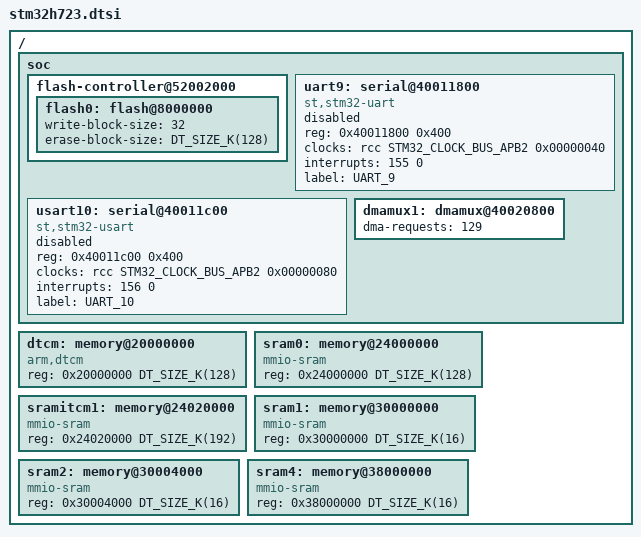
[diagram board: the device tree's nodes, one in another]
/*
 * Copyright (c) 2020 Alexander Kozhinov <AlexanderKozhinov@yandex.com>
 * SPDX-License-Identifier: Apache-2.0
 */

#include <st/h7/stm32h7.dtsi>

/ {
	soc {
		flash-controller@52002000 {
			flash0: flash@8000000 {
				write-block-size = <32>;
				erase-block-size = <DT_SIZE_K(128)>;
			};
		};

		uart9: serial@40011800 {
			compatible = "st,stm32-uart";
			reg = <0x40011800 0x400>;
			clocks = <&rcc STM32_CLOCK_BUS_APB2 0x00000040>;
			interrupts = <155 0>;
			status = "disabled";
			label = "UART_9";
		};

		usart10: serial@40011c00 {
			compatible = "st,stm32-usart", "st,stm32-uart";
			reg = <0x40011c00 0x400>;
			clocks = <&rcc STM32_CLOCK_BUS_APB2 0x00000080>;
			interrupts = <156 0>;
			status = "disabled";
			label = "UART_10";
		};

		dmamux1: dmamux@40020800 {
			dma-requests= <129>;
		};
	};

	/* DTCM memory directly coppled to CPU */
	dtcm: memory@20000000 {
		compatible = "arm,dtcm";
		reg = <0x20000000 DT_SIZE_K(128)>;
	};

	/* System data RAM accessible over AXI bus: AXI SRAM in D1 domain */
	sram0: memory@24000000 {
		compatible = "mmio-sram";
		reg = <0x24000000 DT_SIZE_K(128)>;
	};

	/* System data RAM accessible over AXI/ITCM bus: AXI SRAM in D1 domain
	 * or alternatively ITCM RAM
	 * See "Table 8. ITCM/DTCM/AXI configuration" for proper configuration.
	 */
	sramitcm1: memory@24020000 {
		compatible = "mmio-sram";
		reg = <0x24020000 DT_SIZE_K(192)>;
	};

	/* System data RAM accessible over AHB bus: SRAM1 in D2 domain */
	sram1: memory@30000000 {
		reg = <0x30000000 DT_SIZE_K(16)>;
		compatible = "mmio-sram";
	};

	/* System data RAM accessible over AHB bus: SRAM2 in D2 domain */
	sram2: memory@30004000 {
		compatible = "mmio-sram";
		reg = <0x30004000 DT_SIZE_K(16)>;
	};

	/* System data RAM accessible over AHB bus: SRAM4 in D3 domain  */
	sram4: memory@38000000 {
		compatible = "mmio-sram";
		reg = <0x38000000 DT_SIZE_K(16)>;
	};
};
